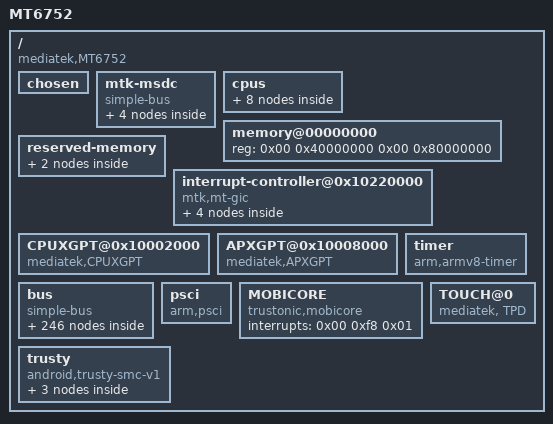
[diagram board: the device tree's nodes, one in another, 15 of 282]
/dts-v1/;

/ {
	model = "MT6752";
	compatible = "mediatek,MT6752";
	interrupt-parent = <0x01>;
	#address-cells = <0x02>;
	#size-cells = <0x02>;

	chosen {
		bootargs = "console=tty0 root=/dev/ram initrd=0x44000000,0x200000 loglevel=8";
	};

	mtk-msdc {
		compatible = "simple-bus";
		#address-cells = <0x01>;
		#size-cells = <0x01>;
		ranges = <0x00 0x00 0x00 0xffffffff>;

		MSDC0@0x11230000 {
			compatible = "mediatek,MSDC0";
			reg = <0x11230000 0x10000 0x10001e84 0x02>;
			interrupts = <0x00 0x4f 0x08>;
		};

		MSDC1@0x11240000 {
			compatible = "mediatek,MSDC1";
			reg = <0x11240000 0x10000 0x10001e84 0x02>;
			interrupts = <0x00 0x50 0x08>;
		};

		MSDC2@0x11250000 {
			compatible = "mediatek,MSDC2";
			reg = <0x11250000 0x10000 0x10001e84 0x02>;
			interrupts = <0x00 0x51 0x08>;
		};

		MSDC3@0x11260000 {
			compatible = "mediatek,MSDC3";
			reg = <0x11260000 0x10000 0x10001e84 0x02>;
			interrupts = <0x00 0x52 0x08>;
		};
	};

	cpus {
		#address-cells = <0x01>;
		#size-cells = <0x00>;

		cpu@0 {
			device_type = "cpu";
			compatible = "arm,cortex-a53";
			reg = <0x00>;
			enable-method = "mt-boot";
			cpu-release-addr = <0x00 0x40000200>;
			clock-frequency = <0x77359400>;
			linux,phandle = <0x02>;
			phandle = <0x02>;
		};

		cpu@1 {
			device_type = "cpu";
			compatible = "arm,cortex-a53";
			reg = <0x01>;
			enable-method = "mt-boot";
			cpu-release-addr = <0x00 0x40000200>;
			clock-frequency = <0x77359400>;
			linux,phandle = <0x03>;
			phandle = <0x03>;
		};

		cpu@2 {
			device_type = "cpu";
			compatible = "arm,cortex-a53";
			reg = <0x02>;
			enable-method = "mt-boot";
			cpu-release-addr = <0x00 0x40000200>;
			clock-frequency = <0x77359400>;
			linux,phandle = <0x04>;
			phandle = <0x04>;
		};

		cpu@3 {
			device_type = "cpu";
			compatible = "arm,cortex-a53";
			reg = <0x03>;
			enable-method = "mt-boot";
			cpu-release-addr = <0x00 0x40000200>;
			clock-frequency = <0x77359400>;
			linux,phandle = <0x05>;
			phandle = <0x05>;
		};

		cpu@4 {
			device_type = "cpu";
			compatible = "arm,cortex-a53";
			reg = <0x100>;
			enable-method = "mt-boot";
			cpu-release-addr = <0x00 0x40000200>;
			clock-frequency = <0x77359400>;
		};

		cpu@5 {
			device_type = "cpu";
			compatible = "arm,cortex-a53";
			reg = <0x101>;
			enable-method = "mt-boot";
			cpu-release-addr = <0x00 0x40000200>;
			clock-frequency = <0x77359400>;
		};

		cpu@6 {
			device_type = "cpu";
			compatible = "arm,cortex-a53";
			reg = <0x102>;
			enable-method = "mt-boot";
			cpu-release-addr = <0x00 0x40000200>;
			clock-frequency = <0x77359400>;
		};

		cpu@7 {
			device_type = "cpu";
			compatible = "arm,cortex-a53";
			reg = <0x103>;
			enable-method = "mt-boot";
			cpu-release-addr = <0x00 0x40000200>;
			clock-frequency = <0x77359400>;
		};
	};

	memory@00000000 {
		device_type = "memory";
		reg = <0x00 0x40000000 0x00 0x80000000>;
	};

	reserved-memory {
		#address-cells = <0x02>;
		#size-cells = <0x02>;
		ranges;

		reserve-memory-ccci_md1 {
			compatible = "reserve-memory-ccci_md1";
			no-map;
			size = <0x00 0x5200000>;
			alignment = <0x00 0x2000000>;
			alloc-ranges = <0x00 0x40000000 0x00 0xc0000000>;
		};

		consys-reserve-memory {
			compatible = "consys-reserve-memory";
			no-map;
			size = <0x00 0x200000>;
			alignment = <0x00 0x200000>;
		};
	};

	interrupt-controller@0x10220000 {
		compatible = "mtk,mt-gic";
		#interrupt-cells = <0x03>;
		#address-cells = <0x00>;
		interrupt-controller;
		reg = <0x00 0x10221000 0x00 0x1000 0x00 0x10222000 0x00 0x1000 0x00 0x10200620 0x00 0x1000>;
		interrupts = <0x01 0x09 0xf04>;
		linux,phandle = <0x01>;
		phandle = <0x01>;

		gic-cpuif@0 {
			compatible = "arm,gic-cpuif";
			cpuif-id = <0x00>;
			cpu = <0x02>;
		};

		gic-cpuif@1 {
			compatible = "arm,gic-cpuif";
			cpuif-id = <0x01>;
			cpu = <0x03>;
		};

		gic-cpuif@2 {
			compatible = "arm,gic-cpuif";
			cpuif-id = <0x02>;
			cpu = <0x04>;
		};

		gic-cpuif@3 {
			compatible = "arm,gic-cpuif";
			cpuif-id = <0x03>;
			cpu = <0x05>;
		};
	};

	CPUXGPT@0x10002000 {
		compatible = "mediatek,CPUXGPT";
		reg = <0x00 0x10200000 0x00 0x1000>;
		interrupts = <0x00 0x40 0x04 0x00 0x41 0x04 0x00 0x42 0x04 0x00 0x43 0x04 0x00 0x44 0x04 0x00 0x45 0x04 0x00 0x46 0x04 0x00 0x47 0x04>;
	};

	APXGPT@0x10008000 {
		compatible = "mediatek,APXGPT";
		reg = <0x00 0x10008000 0x00 0x1000>;
		interrupts = <0x00 0x98 0x08>;
		clock-frequency = <0xc65d40>;
	};

	timer {
		compatible = "arm,armv8-timer";
		interrupts = <0x01 0x0d 0x08 0x01 0x0e 0x08 0x01 0x0b 0x08 0x01 0x0a 0x08>;
		clock-frequency = <0xc65d40>;
	};

	bus {
		compatible = "simple-bus";
		#address-cells = <0x01>;
		#size-cells = <0x01>;
		ranges = <0x00 0x00 0x00 0xffffffff>;

		TOPCKGEN@0x10000000 {
			compatible = "mediatek,TOPCKGEN";
			reg = <0x10000000 0x1000>;
		};

		INFRACFG_AO@0x10001000 {
			compatible = "mediatek,INFRACFG_AO";
			reg = <0x10001000 0x1000>;
		};

		usb2jtag@10001000 {
			compatible = "mediatek,usb2jtag_v1";
			reg = <0x10001000 0x1000 0x11210000 0x1000>;
		};

		IOCFG_L@0x10002000 {
			compatible = "mediatek,IOCFG_L";
			reg = <0x10002000 0x400>;
		};

		IOCFG_B@0x10002400 {
			compatible = "mediatek,IOCFG_B";
			reg = <0x10002400 0x400>;
		};

		IOCFG_R@0x10002800 {
			compatible = "mediatek,IOCFG_R";
			reg = <0x10002800 0x400>;
		};

		IOCFG_T@0x10002C00 {
			compatible = "mediatek,IOCFG_T";
			reg = <0x10002c00 0x400>;
		};

		PERICFG@0x10003000 {
			compatible = "mediatek,PERICFG";
			reg = <0x10003000 0x1000>;
		};

		DRAMC0@0x10004000 {
			compatible = "mediatek,DRAMC0";
			reg = <0x10004000 0x1000>;
		};

		GPIO@0x10005000 {
			compatible = "mediatek,GPIO";
			reg = <0x10005000 0x1000>;
		};

		SLEEP@0x10006000 {
			compatible = "mediatek,SLEEP";
			reg = <0x10006000 0x1000>;
			interrupts = <0x00 0xa3 0x08 0x00 0xa4 0x08 0x00 0xa5 0x08 0x00 0xa6 0x08 0x00 0xa7 0x08 0x00 0xa8 0x08 0x00 0xa9 0x08 0x00 0xaa 0x08>;
		};

		TOPRGU@0x10007000 {
			compatible = "mediatek,TOPRGU";
			reg = <0x10007000 0x1000>;
			interrupts = <0x00 0x80 0x02>;
		};

		RSVD@0x10009000 {
			compatible = "mediatek,RSVD";
			reg = <0x10009000 0x1000>;
		};

		hacc@0x1000A000 {
			compatible = "mediatek,hacc";
			reg = <0x1000a000 0x1000>;
			interrupts = <0x00 0xac 0x08>;
		};

		eintc: EINTC@0x1000B000 {
			compatible = "mtk,mt-eic";
			reg = <0x1000b000 0x1000>;
			interrupts = <0x00 0x99 0x04>;
			#interrupt-cells = <0x02>;
			interrupt-controller;
			max_eint_num = <0x40>;
			mapping_table_entry = <0x40>;
			mapping_table = <0x18 0x18 0x19 0x19 0x1f 0x1a 0x20 0x1b 0x21 0x1c 0x22 0x1d 0x23 0x00 0x24 0x01 0x25 0x02 0x3a 0x1e 0x3b 0x1f 0x3c 0x20 0x3d 0x21 0x3e 0x22 0x3f 0x3f 0x44 0x23 0x45 0x24 0x46 0x25 0x47 0x26 0x48 0x27 0x49 0x28 0x61 0x29 0x72 0x03 0x73 0x04 0x74 0x05 0x75 0x06 0x76 0x07 0x77 0x08 0x78 0x32 0x79 0x36 0x7a 0x2a 0x7b 0x2b 0x7c 0x2c 0x7d 0x2d 0x7e 0x2e 0x7f 0x2f 0x80 0x30 0x81 0x31 0x82 0x0b 0x83 0x0c 0x84 0x0d 0x85 0x0e 0x86 0x09 0x87 0x33 0x88 0x0f 0x89 0x34 0x8a 0x35 0x8b 0x0a 0x8c 0x10 0x8d 0x11 0x8e 0x12 0x8f 0x13 0x90 0x14 0x91 0x15 0x92 0x16 0x93 0x17 0x94 0x37 0x95 0x38 0x96 0x39 0x97 0x3a 0x98 0x3b 0x99 0x3c 0x9a 0x3d 0x9b 0x3e>;
			linux,phandle = <0x06>;
			phandle = <0x06>;

			CHR_STAT@0 {
				compatible = "mediatek, CHR_STAT-eint";
				interrupt-parent = <0x06>;
				interrupts = <0x23 0x08>;
				debounce = <0x23 0x00>;
			};

			GSE_1@2 {
				compatible = "mediatek, GSE_1-eint";
				interrupt-parent = <0x06>;
				interrupts = <0x25 0x04>;
				debounce = <0x25 0x00>;
			};

			MSE@9 {
				compatible = "mediatek, MSE-eint";
				interrupt-parent = <0x06>;
				interrupts = <0x86 0x08>;
				debounce = <0x86 0x00>;
			};

			TOUCH_PANEL@10 {
				compatible = "mediatek, TOUCH_PANEL-eint";
				interrupt-parent = <0x06>;
				interrupts = <0x8b 0x01>;
				debounce = <0x8b 0x00>;
			};

			ALS@11 {
				compatible = "mediatek, ALS-eint";
				interrupt-parent = <0x06>;
				interrupts = <0x82 0x08>;
				debounce = <0x82 0x00>;
			};

			IRQ_NFC@13 {
				compatible = "mediatek, IRQ_NFC-eint";
				interrupt-parent = <0x06>;
				interrupts = <0x84 0x04>;
				debounce = <0x84 0x00>;
			};

			EXT_BUCK_OC@14 {
				compatible = "mediatek, EXT_BUCK_OC-eint";
				interrupt-parent = <0x06>;
				interrupts = <0x85 0x04>;
				debounce = <0x85 0x00>;
			};

			GYRO@17 {
				compatible = "mediatek, GYRO-eint";
				interrupt-parent = <0x06>;
				interrupts = <0x8d 0x04>;
				debounce = <0x8d 0x00>;
			};

			EINT_HDMI_HPD@21 {
				compatible = "mediatek, EINT_HDMI_HPD-eint";
				interrupt-parent = <0x06>;
				interrupts = <0x91 0x08>;
				debounce = <0x91 0x00>;
			};

			MSDC1_INS@22 {
				compatible = "mediatek, MSDC1_INS-eint";
				interrupt-parent = <0x06>;
				interrupts = <0x92 0x04>;
				debounce = <0x92 0x3e8>;
			};

			KPD_SLIDE@23 {
				compatible = "mediatek, KPD_SLIDE-eint";
				interrupt-parent = <0x06>;
				interrupts = <0x93 0x08>;
				debounce = <0x93 0x7d00>;
			};

			ACCDET@40 {
				compatible = "mediatek, ACCDET-eint";
				interrupt-parent = <0x06>;
				interrupts = <0x49 0x08>;
				debounce = <0x49 0x3e80>;
			};
		};

		EMIMPU@0x10203000 {
			compatible = "mediatek,EMIMPU";
			reg = <0x10203000 0x1000>;
			interrupts = <0x00 0x85 0x08>;
		};

		APMIXED@0x1000C000 {
			compatible = "mediatek,APMIXED";
			reg = <0x1000c000 0x1000>;
			interrupts = <0x00 0x88 0x01>;
		};

		FHCTL@0x1000CF00 {
			compatible = "mediatek,FHCTL";
			reg = <0x1000cf00 0x100>;
		};

		PWRAP@0x1000D000 {
			compatible = "mediatek,PWRAP";
			reg = <0x1000d000 0x1000>;
			interrupts = <0x00 0xa1 0x04>;
		};

		DEVAPC_AO@0x1000E000 {
			compatible = "mediatek,DEVAPC_AO";
			reg = <0x1000e000 0x1000>;
		};

		DDRPHY@0x1000F000 {
			compatible = "mediatek,DDRPHY";
			reg = <0x1000f000 0x1000>;
		};

		KP@0x10010000 {
			compatible = "mediatek,KP";
			reg = <0x10010000 0x1000>;
			interrupts = <0x00 0xa2 0x02>;
		};

		TOPMISC@0x10011000 {
			compatible = "mediatek,TOPMISC";
			reg = <0x10011000 0x1000>;
		};

		SCP_SRAM@0x10020000 {
			compatible = "mediatek,SCP_SRAM";
			reg = <0x10020000 0x38000>;
		};

		SCP_CFGREG@0x10058000 {
			compatible = "mediatek,SCP_CFGREG";
			reg = <0x10058000 0x400>;
			interrupts = <0x00 0xae 0x04>;
		};

		SCP_MAD@0x10058400 {
			compatible = "mediatek,SCP_MAD";
			reg = <0x10058400 0x400>;
		};

		SCP_INTC@0x10058800 {
			compatible = "mediatek,SCP_INTC";
			reg = <0x10058800 0x400>;
		};

		SCP_TIMER@0x10058C00 {
			compatible = "mediatek,SCP_TIMER";
			reg = <0x10058c00 0x400>;
		};

		SCP_CLK_CTRL@0x10059000 {
			compatible = "mediatek,SCP_CLK_CTRL";
			reg = <0x10059000 0x400>;
		};

		SCP_I2C0@0x10059400 {
			compatible = "mediatek,SCP_I2C0";
			reg = <0x10059400 0x400>;
		};

		SCP_I2C1@0x10059800 {
			compatible = "mediatek,SCP_I2C1";
			reg = <0x10059800 0x400>;
		};

		SCP_I2C2@0x10059C00 {
			compatible = "mediatek,SCP_I2C2";
			cell-index = <0x02>;
			reg = <0x10059c00 0x400>;
		};

		SCP_GPIO@0x1005A000 {
			compatible = "mediatek,SCP_GPIO";
			reg = <0x1005a000 0x400>;
		};

		SCP_UART@0x1005A400 {
			compatible = "mediatek,SCP_UART";
			reg = <0x1005a400 0x400>;
		};

		SCP_CIRQ_EINT@0x1005A800 {
			compatible = "mediatek,SCP_CIRQ_EINT";
			reg = <0x1005a800 0x400>;
		};

		SCP_PMICWP2P@0x1005E000 {
			compatible = "mediatek,SCP_PMICWP2P";
			reg = <0x1005e000 0x1000>;
		};

		SCP_PMICWP2P@0x1005F000 {
			compatible = "mediatek,SCP_PMICWP2P";
			reg = <0x1005f000 0x1000>;
		};

		DBGAPB_BASE@0x1011A000 {
			compatible = "mediatek,DBGAPB_BASE";
			reg = <0x1011a000 0x100>;
		};

		DBG_ETB@0x10100000 {
			compatible = "mediatek,DBG_ETB";
			reg = <0x10410000 0x10000 0x10430000 0x10000 0x10440000 0x10000 0x104a0000 0x10000>;
		};

		DBG_DEBUG {
			compatible = "mediatek,DBG_DEBUG";
			num = <0x08>;
			reg = <0x10810000 0x1000 0x10910000 0x1000 0x10a10000 0x1000 0x10b10000 0x1000 0x10c10000 0x1000 0x10d10000 0x1000 0x10e10000 0x1000 0x10f10000 0x1000>;
		};

		DBG_ETM {
			compatible = "mediatek,DBG_ETM";
			num = <0x08>;
			reg = <0x10840000 0x1000 0x10940000 0x1000 0x10a40000 0x1000 0x10b40000 0x1000 0x10c40000 0x1000 0x10d40000 0x1000 0x10e40000 0x1000 0x10f40000 0x1000>;
		};

		BAT_METTER {
			compatible = "mediatek,bat_meter";
		};

		BAT_NOTIFY {
			compatible = "mediatek,bat_notify";
		};

		MCUCFG@0x10200000 {
			compatible = "mediatek,MCUCFG";
			reg = <0x10200000 0x1000>;
		};

		INFRACFG@0x10201000 {
			compatible = "mediatek,INFRACFG";
			reg = <0x10201000 0x1000>;
		};

		SRAMROM@0x10202000 {
			compatible = "mediatek,SRAMROM";
			reg = <0x10202000 0x1000>;
		};

		EMI@0x10203000 {
			compatible = "mediatek,EMI";
			reg = <0x10203000 0x1000>;
			interrupts = <0x00 0x87 0x08>;
		};

		sys_cirq@10204000 {
			compatible = "mediatek,SYS_CIRQ";
			reg = <0x10204000 0x1000>;
			interrupts = <0x00 0xf0 0x08>;
			cirq_num = <0xa8>;
			spi_start_offset = <0x48>;
		};

		M4U@0x10205000 {
			cell-index = <0x00>;
			compatible = "mediatek,M4U";
			reg = <0x10205000 0x1000>;
			interrupts = <0x00 0x93 0x08>;
		};

		EFUSEC@0x10206000 {
			compatible = "mediatek,EFUSEC";
			reg = <0x10206000 0x1000>;
			interrupts = <0x00 0x89 0x01>;
		};

		DEVAPC@0x10207000 {
			compatible = "mediatek,DEVAPC";
			reg = <0x10207000 0x1000>;
			interrupts = <0x00 0x86 0x08>;
		};

		BUS_DBG@0x10208000 {
			compatible = "mediatek,BUS_DBG";
			reg = <0x10208000 0x1000>;
			interrupts = <0x00 0x84 0x08>;
		};

		AP_CCIF0@0x10209000 {
			compatible = "mediatek,AP_CCIF0";
			reg = <0x10209000 0x1000>;
		};

		MD_CCIF0@0x1020A000 {
			compatible = "mediatek,MD_CCIF0";
			reg = <0x1020a000 0x1000>;
		};

		AP_CCIF1@0x1020B000 {
			compatible = "mediatek,AP_CCIF1";
			reg = <0x1020b000 0x1000>;
			interrupts = <0x00 0x8d 0x08 0x00 0xaf 0x02>;
			cell-index = <0x01>;
			ccif,major = <0xa9>;
			ccif,minor_base = <0x00>;
			ccif,capability = <0x00>;
			md_smem_size = <0x400000>;
		};

		MD_CCIF1@0x1020C000 {
			compatible = "mediatek,MD_CCIF1";
			reg = <0x1020c000 0x1000>;
		};

		INFRA_MBIST@0x1020D000 {
			compatible = "mediatek,INFRA_MBIST";
			reg = <0x1020d000 0x1000>;
		};

		DRAMC_NAO@0x1020E000 {
			compatible = "mediatek,DRAMC_NAO";
			reg = <0x1020e000 0x1000>;
		};

		TRNG@0x1020F000 {
			compatible = "mediatek,TRNG";
			reg = <0x1020f000 0x1000>;
			interrupts = <0x00 0x8c 0x08>;
		};

		GCPU@0x10210000 {
			compatible = "mediatek,gcpu";
			reg = <0x10210000 0x1000>;
			interrupts = <0x00 0x96 0x08>;
		};

		MD2MD_MD1_CCIF0@0x10211000 {
			compatible = "mediatek,MD2MD_MD1_CCIF0";
			reg = <0x10211000 0x1000>;
		};

		gce@10212000 {
			compatible = "mediatek,gce";
			reg = <0x10212000 0x1000>;
			interrupts = <0x00 0x8f 0x08 0x00 0x90 0x08>;
			disp_mutex_reg = <0x14015000 0x1000>;
			g3d_config_base = <0x13000000 0x00 0xffff0000>;
			mmsys_config_base = <0x14000000 0x01 0xffff0000>;
			disp_dither_base = <0x14010000 0x02 0xffff0000>;
			mm_na_base = <0x14020000 0x03 0xffff0000>;
			imgsys_base = <0x15000000 0x04 0xffff0000>;
			vdec_gcon_base = <0x16000000 0x05 0xffff0000>;
			venc_gcon_base = <0x17000000 0x06 0xffff0000>;
			conn_peri_base = <0x18000000 0x07 0xffff0000>;
			topckgen_base = <0x10000000 0x08 0xffff0000>;
			kp_base = <0x10010000 0x09 0xffff0000>;
			scp_sram_base = <0x10020000 0x0a 0xffff0000>;
			infra_na3_base = <0x10030000 0x0b 0xffff0000>;
			infra_na4_base = <0x10040000 0x0c 0xffff0000>;
			scp_base = <0x10050000 0x0d 0xffff0000>;
			mcucfg_base = <0x10200000 0x0e 0xffff0000>;
			gcpu_base = <0x10210000 0x0f 0xffff0000>;
			usb0_base = <0x11200000 0x10 0xffff0000>;
			usb_sif_base = <0x11210000 0x11 0xffff0000>;
			audio_base = <0x11220000 0x12 0xffff0000>;
			msdc0_base = <0x11230000 0x13 0xffff0000>;
			msdc1_base = <0x11240000 0x14 0xffff0000>;
			msdc2_base = <0x11250000 0x15 0xffff0000>;
			msdc3_base = <0x11260000 0x16 0xffff0000>;
			mdp_rdma0_sof = <0x00>;
			mdp_rsz0_sof = <0x01>;
			mdp_rsz1_sof = <0x02>;
			mdp_tdshp_sof = <0x03>;
			mdp_wdma_sof = <0x04>;
			mdp_wrot_sof = <0x05>;
			disp_ovl0_sof = <0x06>;
			disp_ovl1_sof = <0x07>;
			disp_rdma0_sof = <0x08>;
			disp_rdma1_sof = <0x09>;
			disp_wdma0_sof = <0x0a>;
			disp_color_sof = <0x0b>;
			disp_ccorr_sof = <0x0c>;
			disp_aal_sof = <0x0d>;
			disp_gamma_sof = <0x0e>;
			disp_dither_sof = <0x0f>;
			disp_ufoe_sof = <0x10>;
			disp_pwm0_sof = <0x11>;
			disp_wdma1_sof = <0x12>;
			ufod_rdma0_l0_sof = <0x13>;
			ufod_rdma0_l1_sof = <0x14>;
			ufod_rdma0_l2_sof = <0x15>;
			ufod_rdma0_l3_sof = <0x16>;
			ufod_rdma1_l0_sof = <0x17>;
			ufod_rdma1_l1_sof = <0x18>;
			ufod_rdma1_l2_sof = <0x19>;
			ufod_rdma1_l3_sof = <0x1a>;
			mdp_rdma0_frame_done = <0x1b>;
			mdp_rsz0_frame_done = <0x1c>;
			mdp_rsz1_frame_done = <0x1d>;
			mdp_tdshp_frame_done = <0x1e>;
			mdp_wdma_frame_done = <0x1f>;
			mdp_wrot_write_frame_done = <0x20>;
			mdp_wrot_read_frame_done = <0x21>;
			disp_ovl0_frame_done = <0x22>;
			disp_ovl1_frame_done = <0x23>;
			disp_rdma0_frame_done = <0x24>;
			disp_rdma1_frame_done = <0x25>;
			disp_wdma0_frame_done = <0x26>;
			disp_color_frame_done = <0x27>;
			disp_ccorr_frame_done = <0x28>;
			disp_aal_frame_done = <0x29>;
			disp_gamma_frame_done = <0x2a>;
			disp_dither_frame_done = <0x2b>;
			disp_ufoe_frame_done = <0x2c>;
			disp_dpi0_frame_done = <0x2d>;
			disp_wdma1_frame_done = <0x2e>;
			ufod_rdma0_l0_frame_done = <0x2f>;
			ufod_rdma0_l1_frame_done = <0x30>;
			ufod_rdma0_l2_frame_done = <0x31>;
			ufod_rdma0_l3_frame_done = <0x32>;
			ufod_rdma1_l0_frame_done = <0x33>;
			ufod_rdma1_l1_frame_done = <0x34>;
			ufod_rdma1_l2_frame_done = <0x35>;
			ufod_rdma1_l3_frame_done = <0x36>;
			stream_done_0 = <0x37>;
			stream_done_1 = <0x38>;
			stream_done_2 = <0x39>;
			stream_done_3 = <0x3a>;
			stream_done_4 = <0x3b>;
			stream_done_5 = <0x3c>;
			stream_done_6 = <0x3d>;
			stream_done_7 = <0x3e>;
			stream_done_8 = <0x3f>;
			stream_done_9 = <0x40>;
			buf_underrun_event_0 = <0x41>;
			buf_underrun_event_1 = <0x42>;
			dsi0_te_event = <0x43>;
			isp_frame_done_p2_2 = <0x81>;
			isp_frame_done_p2_1 = <0x82>;
			isp_frame_done_p2_0 = <0x83>;
			isp_frame_done_p1_1 = <0x84>;
			isp_frame_done_p1_0 = <0x85>;
			camsv_2_pass1_done = <0x86>;
			camsv_1_pass1_done = <0x87>;
			seninf_cam1_2_3_fifo_full = <0x88>;
			seninf_cam0_fifo_full = <0x89>;
			venc_done = <0x101>;
			jpgenc_done = <0x102>;
			jpgdec_done = <0x103>;
			venc_mb_done = <0x104>;
			venc_128byte_cnt_done = <0x105>;
			apxgpt2_count = <0x10008028>;
		};

		MD2MD_MD2_CCIF0@0x10213000 {
			compatible = "mediatek,MD2MD_MD2_CCIF0";
			reg = <0x10213000 0x1000>;
		};

		PERISYS_IOMMU@0x10214000 {
			cell-index = <0x01>;
			compatible = "mediatek,PERISYS_IOMMU";
			reg = <0x10214000 0x1000>;
			interrupts = <0x00 0x91 0x08>;
		};

		MIPI_TX0@0x10215000 {
			compatible = "mediatek,MIPI_TX0";
			reg = <0x10215000 0x1000>;
		};

		MIPI_RX_ANA_CSI0@0x10217000 {
			compatible = "mediatek,MIPI_RX_ANA_CSI0";
			reg = <0x10217000 0x1000>;
			interrupts = <0x00 0x8a 0x01>;
		};

		MIPI_RX_ANA_CSI1@0x10218000 {
			compatible = "mediatek,MIPI_RX_ANA_CSI1";
			reg = <0x10218000 0x1000>;
		};

		GIC@0x10220000 {
			compatible = "mediatek,GIC";
			reg = <0x10220000 0x8000>;
		};

		CCI400@0x10390000 {
			compatible = "mediatek,CCI400";
			reg = <0x10390000 0x10000>;
		};

		DBGAPB@0x10400000 {
			compatible = "mediatek,DBGAPB";
			reg = <0x10400000 0xc00000>;
			interrupts = <0x00 0x83 0x08>;
		};

		AP_DMA@0x11000000 {
			compatible = "mediatek,AP_DMA";
			reg = <0x11000000 0x1000>;
			interrupts = <0x00 0x6f 0x08>;
		};

		AUXADC@0x11001000 {
			compatible = "mediatek,AUXADC";
			reg = <0x11001000 0x1000>;
			interrupts = <0x00 0x4c 0x02>;
		};

		AP_DMA_UART0_TX@0x11000300 {
			compatible = "mediatek,AP_DMA_UART0_TX";
			reg = <0x11000300 0x80>;
			interrupts = <0x00 0x66 0x08>;
		};

		AP_DMA_UART0_RX@0x11000380 {
			compatible = "mediatek,AP_DMA_UART0_RX";
			reg = <0x11000380 0x80>;
			interrupts = <0x00 0x67 0x08>;
		};

		AP_DMA_UART1_TX@0x11000400 {
			compatible = "mediatek,AP_DMA_UART1_TX";
			reg = <0x11000400 0x80>;
			interrupts = <0x00 0x68 0x08>;
		};

		AP_DMA_UART1_RX@0x11000480 {
			compatible = "mediatek,AP_DMA_UART1_RX";
			reg = <0x11000480 0x80>;
			interrupts = <0x00 0x69 0x08>;
		};

		AP_DMA_UART2_TX@0x11000500 {
			compatible = "mediatek,AP_DMA_UART2_TX";
			reg = <0x11000500 0x80>;
			interrupts = <0x00 0x6a 0x08>;
		};

		AP_DMA_UART2_RX@0x11000580 {
			compatible = "mediatek,AP_DMA_UART2_RX";
			reg = <0x11000580 0x80>;
			interrupts = <0x00 0x6b 0x08>;
		};

		AP_DMA_UART3_TX@0x11000600 {
			compatible = "mediatek,AP_DMA_UART3_TX";
			reg = <0x11000600 0x80>;
			interrupts = <0x00 0x6c 0x08>;
		};

		AP_DMA_UART3_RX@0x11000680 {
			compatible = "mediatek,AP_DMA_UART3_RX";
			reg = <0x11000680 0x80>;
			interrupts = <0x00 0x6d 0x08>;
		};

		AP_UART0@0x11002000 {
			cell-index = <0x00>;
			compatible = "mediatek,AP_UART0";
			reg = <0x11002000 0x1000>;
			interrupts = <0x00 0x5b 0x08>;
		};

		AP_UART1@0x11003000 {
			cell-index = <0x01>;
			compatible = "mediatek,AP_UART1";
			reg = <0x11003000 0x1000>;
			interrupts = <0x00 0x5c 0x08>;
		};

		AP_UART2@0x11004000 {
			cell-index = <0x02>;
			compatible = "mediatek,AP_UART2";
			reg = <0x11004000 0x1000>;
			interrupts = <0x00 0x5d 0x08>;
		};

		AP_UART3@0x11005000 {
			cell-index = <0x03>;
			compatible = "mediatek,AP_UART3";
			reg = <0x11005000 0x1000>;
			interrupts = <0x00 0x5e 0x08>;
		};

		PWM@0x11006000 {
			compatible = "mediatek,PWM";
			reg = <0x11006000 0x1000>;
			interrupts = <0x00 0x4d 0x08>;
		};

		I2C0@0x11007000 {
			compatible = "mediatek,I2C0";
			cell-index = <0x00>;
			reg = <0x11007000 0x1000>;
			#address-cells = <0x01>;
			#size-cells = <0x00>;
			interrupts = <0x00 0x54 0x08>;

			// gt9xx@5d {
			//	compatible = "gt9xx";
			//	reg = <0x5d>;
			//};

			//bq24296@6b {
			//	compatible = "bq24296";
			//	reg = <0x6b>;
			//};

			//mt6306@64 {
			//	compatible = "mediatek,mt6306";
			//	reg = <0x64>;
			//};
		};

		I2C1@0x11008000 {
			compatible = "mediatek,I2C1";
			cell-index = <0x01>;
			reg = <0x11008000 0x1000>;
			#address-cells = <0x01>;
			#size-cells = <0x00>;
			interrupts = <0x00 0x55 0x08>;

			//yas530@2e {
			//	compatible = "yamaha530";
			//	reg = <0x2e>;
			//};

			/* mpu-6515@68 {
				compatible = "mpu-6515";
				reg = <0x68>;
			};

			bmp180@77 {
				compatible = "bmp180";
				reg = <0x77>;
			};

			cm36652@60 {
				compatble = "cm36652";
				reg = <0x60>;
			};

			mt6605@28 {
				compatible = "mediatek,mt6605";
				reg = <0x28>;
			}; */
		};

		I2C2@0x11009000 {
			compatible = "mediatek,I2C2";
			cell-index = <0x03>;
			reg = <0x11009000 0x1000>;
			#address-cells = <0x01>;
			#size-cells = <0x00>;
			interrupts = <0x00 0x56 0x08>;
		};

		SPI1@0x1100A000 {
			compatible = "mediatek,SPI1";
			cell-index = <0x00>;
			spi-padmacro = <0x00>;
			reg = <0x1100a000 0x1000>;
			interrupts = <0x00 0x76 0x08>;
		};

		THERM_CTRL@0x1100B000 {
			compatible = "mediatek,THERM_CTRL";
			reg = <0x1100b000 0x1000>;
			interrupts = <0x00 0x4e 0x08>;
		};

		PTP_FSM@0x1100B000 {
			compatible = "mediatek,PTP_FSM";
			reg = <0x1100b000 0x1000>;
			interrupts = <0x00 0x7d 0x08>;
		};

		AP_DMA_BTIF_TX@0x11000700 {
			compatible = "mediatek,AP_DMA_BTIF_TX";
			reg = <0x11000700 0x80>;
			interrupts = <0x00 0x6e 0x08>;
		};

		AP_DMA_BTIF_RX@0x11000780 {
			compatible = "mediatek,AP_DMA_BTIF_RX";
			reg = <0x11000780 0x80>;
			interrupts = <0x00 0x6f 0x08>;
		};

		BTIF@0x1100C000 {
			compatible = "mediatek,BTIF";
			reg = <0x1100c000 0x1000>;
			interrupts = <0x00 0x70 0x08>;
		};

		mt3326-gps@0xffffffff {
			compatible = "mediatek,mt3326-gps";
		};

		BTCVSD@0x18000000 {
			compatible = "mediatek,audio_bt_cvsd";
			offset = <0xf00 0x800 0xfd0 0xfd4 0xfd8>;
			reg = <0x10001000 0x1000 0x18000000 0x10000 0x18080000 0x8000>;
			interrupts = <0x00 0xec 0x08>;
		};

		CONSYS@0x18070000 {
			compatible = "mediatek,CONSYS";
			reg = <0x18070000 0x200 0x10007000 0x100 0x10000000 0x2000 0x10006000 0x1000>;
			interrupts = <0x00 0xed 0x08 0x00 0xeb 0x08>;
		};

		WIFI@0x180F0000 {
			compatible = "mediatek,WIFI";
			reg = <0x180f0000 0x5c>;
			interrupts = <0x00 0xee 0x08>;
		};

		NFI@0x1100D000 {
			compatible = "mediatek,NFI";
			reg = <0x1100d000 0x1000>;
			interrupts = <0x00 0x60 0x08>;
		};

		NFIECC@0x1100E000 {
			compatible = "mediatek,NFIECC";
			reg = <0x1100e000 0x1000>;
			interrupts = <0x00 0x5f 0x08>;
		};

		USB0@0x11200000 {
			compatible = "mediatek,USB0";
			cell-index = <0x00>;
			reg = <0x11200000 0x10000 0x11210000 0x10000>;
			interrupts = <0x00 0x48 0x08>;
			mode = <0x02>;
			multipoint = <0x01>;
			dyn_fifo = <0x01>;
			soft_con = <0x01>;
			dma = <0x01>;
			num_eps = <0x10>;
			dma_channels = <0x08>;
			iddig_gpio = <0x8e 0x01>;
			drvvbus_gpio = <0x8f 0x00>;
		};

		BATTERY {
			compatible = "mediatek,battery";
		};

		AUDIO@0x11220000 {
			compatible = "mediatek,AUDIO";
			reg = <0x11220000 0x10000>;
			interrupts = <0x00 0x8e 0x08>;
		};

		MT_SOC_DL1_PCM@0x11220000 {
			compatible = "mediatek,mt_soc_pcm_dl1";
			reg = <0x11220000 0x1000>;
			interrupts = <0x00 0x8e 0x08>;
			audclk-gpio = <0x18 0x00>;
			audmiso-gpio = <0x19 0x00>;
			audmosi-gpio = <0x1a 0x00>;
			vowclk-gpio = <0x94 0x00>;
			extspkamp-gpio = <0x4e 0x00>;
			i2s1clk-gpio = <0x87 0x00>;
			i2s1dat-gpio = <0x89 0x00>;
			i2s1mclk-gpio = <0x86 0x00>;
			i2s1ws-gpio = <0x88 0x00>;
		};

		MT_SOC_UL1_PCM@0x11220000 {
			compatible = "mediatek,mt_soc_pcm_capture";
		};

		MT_SOC_VOICE_MD1@0x11220000 {
			compatible = "mediatek,mt_soc_pcm_voice_md1";
		};

		MT_SOC_HDMI_PCM@0x11220000 {
			compatible = "mediatek,mt_soc_pcm_hdmi";
		};

		MT_SOC_ULDLLOOPBACK_PCM@0x11220000 {
			compatible = "mediatek,mt_soc_pcm_uldlloopback";
		};

		MT_SOC_I2S0_PCM@0x11220000 {
			compatible = "mediatek,mt_soc_pcm_dl1_i2s0";
		};

		MT_SOC_MRGRX_PCM@0x11220000 {
			compatible = "mediatek,mt_soc_pcm_mrgrx";
		};

		MT_SOC_MRGRX_AWB_PCM@0x11220000 {
			compatible = "mediatek,mt_soc_pcm_mrgrx_awb";
		};

		MT_SOC_FM_I2S_PCM@0x11220000 {
			compatible = "mediatek,mt_soc_pcm_fm_i2s";
		};

		MT_SOC_FM_I2S_AWB_PCM@0x11220000 {
			compatible = "mediatek,mt_soc_pcm_fm_i2s_awb";
		};

		MT_SOC_I2S0DL1_PCM@0x11220000 {
			compatible = "mediatek,mt_soc_pcm_dl1_i2s0Dl1";
		};

		MT_SOC_DL1_AWB_PCM@0x11220000 {
			compatible = "mediatek,mt_soc_pcm_dl1_awb";
		};

		MT_SOC_VOICE_MD1_BT@0x11220000 {
			compatible = "mediatek,mt_soc_pcm_voice_md1_bt";
		};

		MT_SOC_VOIP_BT_OUT@0x11220000 {
			compatible = "mediatek,mt_soc_pcm_dl1_bt";
		};

		MT_SOC_VOIP_BT_IN@0x11220000 {
			compatible = "mediatek,mt_soc_pcm_bt_dai";
		};

		MT_SOC_TDMRX_PCM@0x11220000 {
			compatible = "mediatek,mt_soc_tdm_capture";
		};

		MT_SOC_FM_MRGTX_PCM@0x11220000 {
			compatible = "mediatek,mt_soc_pcm_fmtx";
		};

		MT_SOC_UL2_PCM@0x11220000 {
			compatible = "mediatek,mt_soc_pcm_capture2";
		};

		MT_SOC_I2S0_AWB_PCM@0x11220000 {
			compatible = "mediatek,mt_soc_pcm_i2s0_awb";
		};

		MT_SOC_VOICE_MD2@0x11220000 {
			compatible = "mediatek,mt_soc_pcm_voice_md2";
		};

		MT_SOC_ROUTING_PCM@0x11220000 {
			compatible = "mediatek,mt_soc_pcm_routing";
		};

		MT_SOC_VOICE_MD2_BT@0x11220000 {
			compatible = "mediatek,mt_soc_pcm_voice_md2_bt";
		};

		MT_SOC_HP_IMPEDANCE_PCM@0x11220000 {
			compatible = "mediatek,Mt_soc_pcm_hp_impedance";
		};

		MT_SOC_CODEC_NAME@0x11220000 {
			compatible = "mediatek,mt_soc_codec_63xx";
		};

		MT_SOC_DUMMY_PCM@0x11220000 {
			compatible = "mediatek,mt_soc_pcm_dummy";
		};

		MT_SOC_CODEC_DUMMY_NAME@0x11220000 {
			compatible = "mediatek,mt_soc_codec_dummy";
		};

		MT_SOC_ROUTING_DAI_NAME@0x11220000 {
			compatible = "mediatek,mt_soc_dai_routing";
		};

		MT_SOC_DAI_NAME@0x11220000 {
			compatible = "mediatek,mt_soc_dai_stub";
		};

		MT_SOC_DL2_PCM@0x11220000 {
			compatible = "mediatek,mt_soc_pcm_dl2";
		};

		ICUSB@0x11270000 {
			compatible = "mediatek,ICUSB";
			reg = <0x11270000 0x10000 0x11210000 0x10000>;
			interrupts = <0x00 0x49 0x08>;
		};

		G3D_CONFIG@0x13000000 {
			compatible = "mediatek,G3D_CONFIG";
			reg = <0x13000000 0x1000>;
		};

		MALI@0x13040000 {
			compatible = "arm,malit760", "arm,mali-t76x", "arm,malit7xx", "arm,mali-midgard";
			reg = <0x13040000 0x4000>;
			interrupts = <0x00 0xe3 0x08>, <0x00 0xe2 0x08>, <0x00 0xe1 0x08>;
			interrupt-names = "JOB", "MMU", "GPU";
			clock-frequency = <0x29b92700>;
		};

		MMSYS_CONFIG@0x14000000 {
			compatible = "mediatek,MMSYS_CONFIG";
			reg = <0x14000000 0x1000>;
		};

		mdp_rdma@14001000 {
			compatible = "mediatek,mdp_rdma";
			reg = <0x14001000 0x1000>;
			interrupts = <0x00 0xb2 0x08>;
		};

		mdp_rsz0@14002000 {
			compatible = "mediatek,mdp_rsz0";
			reg = <0x14002000 0x1000>;
			interrupts = <0x00 0xb3 0x08>;
		};

		mdp_rsz1@14003000 {
			compatible = "mediatek,mdp_rsz1";
			reg = <0x14003000 0x1000>;
			interrupts = <0x00 0xb4 0x08>;
		};

		mdp_wdma@14004000 {
			compatible = "mediatek,mdp_wdma";
			reg = <0x14004000 0x1000>;
			interrupts = <0x00 0xb6 0x08>;
		};

		mdp_wrot@14005000 {
			compatible = "mediatek,mdp_wrot";
			reg = <0x14005000 0x1000>;
			interrupts = <0x00 0xb7 0x08>;
		};

		mdp_tdshp@14006000 {
			compatible = "mediatek,mdp_tdshp";
			reg = <0x14006000 0x1000>;
			interrupts = <0x00 0xb5 0x08>;
		};

		DISPSYS@0x10002000 {
			compatible = "mediatek,DISPSYS";
			reg = <0x14007000 0x1000 0x14008000 0x1000 0x14009000 0x1000 0x1400a000 0x1000 0x1400b000 0x1000 0x1400c000 0x1000 0x1400d000 0x1000 0x1400e000 0x1000 0x1400f000 0x1000 0x14010000 0x1000 0x14011000 0x1000 0x14014000 0x1000 0x14018000 0x1000 0x14015000 0x1000 0x14012000 0x1000 0x14013000 0x1000 0x14000000 0x1000 0x14016000 0x1000 0x14017000 0x1000 0x10215000 0x1000 0x10206000 0x1000 0x10000000 0x1000 0x100020f0 0x1000 0x100000a0 0x1000 0x1000c270 0x1000 0x1000c274 0x1000>;
			interrupts = <0x00 0xb8 0x08 0x00 0xb9 0x08 0x00 0xba 0x08 0x00 0xbb 0x08 0x00 0xbc 0x08 0x00 0xbd 0x08 0x00 0xbe 0x08 0x00 0xbf 0x08 0x00 0xc0 0x08 0x00 0xc1 0x08 0x00 0xc2 0x08 0x00 0x00 0x08 0x00 0xc6 0x08 0x00 0xb1 0x08 0x00 0xc3 0x08 0x00 0xc4 0x08 0x00 0x00 0x08 0x00 0x00 0x08 0x00 0x00 0x08>;
		};

		DISP_OVL0@0x14007000 {
			compatible = "mediatek,DISP_OVL0";
			reg = <0x14007000 0x1000>;
			interrupts = <0x00 0xb8 0x08>;
		};

		DISP_OVL1@0x14008000 {
			compatible = "mediatek,DISP_OVL1";
			reg = <0x14008000 0x1000>;
			interrupts = <0x00 0xb9 0x08>;
		};

		DISP_RDMA0@0x14009000 {
			compatible = "mediatek,DISP_RDMA0";
			reg = <0x14009000 0x1000>;
			interrupts = <0x00 0xc7 0x08>;
		};

		DISP_RDMA1@0x1400A000 {
			compatible = "mediatek,DISP_RDMA1";
			reg = <0x1400a000 0x1000>;
			interrupts = <0x00 0xc8 0x08>;
		};

		DISP_WDMA0@0x1400B000 {
			compatible = "mediatek,DISP_WDMA0";
			reg = <0x1400b000 0x1000>;
			interrupts = <0x00 0xc6 0x08>;
		};

		DISP_COLOR@0x1400C000 {
			compatible = "mediatek,DISP_COLOR";
			reg = <0x1400c000 0x1000>;
			interrupts = <0x00 0xbd 0x08>;
		};

		DISP_CCORR@0x1400D000 {
			compatible = "mediatek,DISP_CCORR";
			reg = <0x1400d000 0x1000>;
			interrupts = <0x00 0xbe 0x08>;
		};

		DISP_AAL@0x1400E000 {
			compatible = "mediatek,DISP_AAL";
			reg = <0x1400e000 0x1000>;
			interrupts = <0x00 0xbf 0x08>;
		};

		DISP_GAMMA@0x1400F000 {
			compatible = "mediatek,DISP_GAMMA";
			reg = <0x1400f000 0x1000>;
			interrupts = <0x00 0xc0 0x08>;
		};

		DISP_DITHER@0x14010000 {
			compatible = "mediatek,DISP_DITHER";
			reg = <0x14010000 0x1000>;
			interrupts = <0x00 0xc1 0x08>;
		};

		DSI_UFOE@0x14011000 {
			compatible = "mediatek,DSI_UFOE";
			reg = <0x14011000 0x1000>;
		};

		DSI0@0x14012000 {
			compatible = "mediatek,DSI0";
			reg = <0x14012000 0x1000>;
			interrupts = <0x00 0xc3 0x08>;
		};

		DPI0@0x14013000 {
			compatible = "mediatek,DPI0";
			reg = <0x14013000 0x1000>;
			interrupts = <0x00 0xc4 0x08>;
		};

		DISP_PWM0@0x14014000 {
			compatible = "mediatek,DISP_PWM0";
			reg = <0x14014000 0x1000>;
		};

		MM_MUTEX@0x14015000 {
			compatible = "mediatek,MM_MUTEX";
			reg = <0x14015000 0x1000>;
			interrupts = <0x00 0xb1 0x08>;
		};

		SMI_LARB0@0x14016000 {
			compatible = "mediatek,SMI_LARB0";
			reg = <0x14016000 0x1000>;
			interrupts = <0x00 0xcd 0x08>;
		};

		SMI_COMMON@0x14017000 {
			compatible = "mediatek,SMI_COMMON";
			reg = <0x14017000 0x1000 0x14016000 0x1000 0x16010000 0x1000 0x15001000 0x1000 0x17001000 0x1000 0x12002000 0x1000>;
		};

		DISP_WDMA1@0x14018000 {
			compatible = "mediatek,DISP_WDMA1";
			reg = <0x14018000 0x1000>;
		};

		UFOD_RDMA0@0x14019000 {
			compatible = "mediatek,UFOD_RDMA0";
			reg = <0x14019000 0x1000>;
		};

		UFOD_RDMA1@0x1401A000 {
			compatible = "mediatek,UFOD_RDMA1";
			reg = <0x1401a000 0x1000>;
		};

		IMGSYS_CONFIG@0x15000000 {
			compatible = "mediatek,IMGSYS_CONFIG";
			reg = <0x15000000 0x1000>;
		};

		SMI_LARB2@0x15001000 {
			compatible = "mediatek,SMI_LARB2";
			reg = <0x15001000 0x1000>;
			interrupts = <0x00 0xd9 0x08>;
		};

		ISPSYS@0x15000000 {
			compatible = "mediatek,ISPSYS";
			reg = <0x15004000 0x9000 0x1500d000 0x1000 0x15000000 0x10000 0x10217000 0x3000 0x10002000 0x1000>;
			interrupts = <0x00 0xdb 0x08 0x00 0xdc 0x08 0x00 0xdd 0x08 0x00 0xde 0x08 0x00 0xdf 0x08>;
		};

		KD_CAMERA_HW1@0x15008000 {
			compatible = "mediatek,CAMERA_HW";
			reg = <0x15008000 0x1000>;
		};

		KD_CAMERA_HW2@0x15008000 {
			compatible = "mediatek,CAMERA_HW2";
			reg = <0x15008000 0x1000>;
		};

		CAM0@0x15004000 {
			compatible = "mediatek,CAM0";
			reg = <0x15004000 0x2000>;
			interrupts = <0x00 0xdb 0x08>;
		};

		CAM1@0x15006000 {
			compatible = "mediatek,CAM1";
			reg = <0x15006000 0x1000>;
			interrupts = <0x00 0xdc 0x08>;
		};

		CAM2@0x15007000 {
			compatible = "mediatek,CAM2";
			reg = <0x15007000 0x1000>;
			interrupts = <0x00 0xdd 0x08>;
		};

		SENINF@0x15008000 {
			compatible = "mediatek,SENINF";
			reg = <0x15008000 0x1000>;
		};

		CAMSV0@0x15009000 {
			compatible = "mediatek,CAMSV0";
			reg = <0x15009000 0x800>;
			interrupts = <0x00 0xde 0x08>;
		};

		CAMSV1@0x15009800 {
			compatible = "mediatek,CAMSV1";
			reg = <0x15009800 0x800>;
			interrupts = <0x00 0xdf 0x08>;
		};

		FD@0x1500B000 {
			compatible = "mediatek,FD";
			reg = <0x1500b000 0x1000>;
			interrupts = <0x00 0xe0 0x08>;
		};

		MIPI_RX@0x1500C000 {
			compatible = "mediatek,MIPI_RX";
			reg = <0x1500c000 0x1000>;
		};

		CAM0_INNER@0x1500D000 {
			compatible = "mediatek,CAM0_INNER";
			reg = <0x1500d000 0x1000>;
		};

		CAM2_INNER@0x1500E000 {
			compatible = "mediatek,CAM2_INNER";
			reg = <0x1500e000 0x1000>;
		};

		CAM3_INNER@0x1500F000 {
			compatible = "mediatek,CAM3_INNER";
			reg = <0x1500f000 0x1000>;
		};

		VDEC_GCON@16000000 {
			compatible = "mediatek,VDEC_GCON";
			reg = <0x16000000 0x10000>;
		};

		SMI_LARB1@16010000 {
			compatible = "mediatek,SMI_LARB1";
			reg = <0x16010000 0x10000>;
			interrupts = <0x00 0xd5 0x08>;
		};

		VDEC@16020000 {
			compatible = "mediatek,VDEC";
			reg = <0x16020000 0x10000>;
			interrupts = <0x00 0xd4 0x08>;
		};

		MJC_CONFIG@0x12000000 {
			compatible = "mediatek,MJC_CONFIG";
			reg = <0x12000000 0x1000>;
		};

		MJC_TOP@0x12001000 {
			compatible = "mediatek,MJC_TOP";
			reg = <0x12001000 0x1000>;
			interrupts = <0x00 0xd7 0x08>;
		};

		SMI_LARB5@0x12002000 {
			compatible = "mediatek,SMI_LARB5";
			reg = <0x12002000 0x1000>;
		};

		VENC_GCON@17000000 {
			compatible = "mediatek,VENC_GCON";
			reg = <0x17000000 0x1000>;
		};

		SMI_LARB3@17001000 {
			compatible = "mediatek,SMI_LARB3";
			reg = <0x17001000 0x1000>;
			interrupts = <0x00 0xcf 0x08>;
		};

		VENC@17002000 {
			compatible = "mediatek,VENC";
			reg = <0x17002000 0x1000>;
			interrupts = <0x00 0xce 0x08>;
		};

		JPGENC@17003000 {
			compatible = "mediatek,JPGENC";
			reg = <0x17003000 0x1000>;
			interrupts = <0x00 0xd0 0x08>;
		};

		JPGDEC@17004000 {
			compatible = "mediatek,JPGDEC";
			reg = <0x17004000 0x1000>;
			interrupts = <0x00 0xd3 0x08>;
		};

		gpio@0x10001e00 {
			compatible = "mediatek,fpga_gpio";
			reg = <0x10001e00 0x100>;
		};

		MDCLDMA@0x200F0000 {
			compatible = "mediatek,MDCLDMA";
			reg = <0x200f0000 0x3000 0x200e0000 0x3000 0x10209000 0x1000>;
			cell-index = <0x00>;
			interrupts = <0x00 0xe9 0x04 0x00 0x8b 0x08 0x00 0xe8 0x02>;
			cldma,major = <0xb8>;
			cldma,minor_base = <0x00>;
			cldma,capability = <0x02>;
			md_smem_size = <0x200000>;
		};

		HDMI@0 {
			compatible = "mediatek,HDMI";
		};

		hwmsensor@0 {
			compatible = "mediatek,hwmsensor";
		};

		gsensor@0 {
			compatible = "mediatek,gsensor";
		};

		als_ps@0 {
			compatible = "mediatek,als_ps";
		};

		m_acc_pl@0 {
			compatible = "mediatek,m_acc_pl";
		};

		m_alsps_pl@0 {
			compatible = "mediatek,m_alsps_pl";
		};

		sensorHub@0 {
			compatible = "mediatek,sensorHub";
		};

		shf@0 {
			compatible = "mediatek,shf";
		};

		m_batch_pl@0 {
			compatible = "mediatek,m_batch_pl";
		};

		gyroscope@0 {
			compatible = "mediatek,gyroscope";
		};

		m_gyro_pl@0 {
			compatible = "mediatek,m_gyro_pl";
		};

		barometer@0 {
			compatible = "mediatek,barometer";
		};

		m_baro_pl@0 {
			compatible = "mediatek,m_baro_pl";
		};

		msensor@0 {
			compatible = "mediatek,msensor";
		};

		m_mag_pl@0 {
			compatible = "mediatek,m_mag_pl";
		};

		orientation@0 {
			compatible = "mediatek,orientation";
		};

		pedometer@0 {
			compatible = "mediatek,pedometer";
		};

		m_pdr_pl@0 {
			compatible = "mediatek,m_pdr_pl";
		};

		step_counter@0 {
			compatible = "mediatek,step_counter";
		};

		m_step_c_pl@0 {
			compatible = "mediatek,m_step_c_pl";
		};

		in_pocket@0 {
			compatible = "mediatek,in_pocket";
		};

		m_inpk_pl@0 {
			compatible = "mediatek,m_inpk_pl";
		};

		shake@0 {
			compatible = "mediatek,shake";
		};

		m_shk_pl@0 {
			compatible = "mediatek,m_shk_pl";
		};

		face_down@0 {
			compatible = "mediatek,face_down";
		};

		m_fdn_pl@0 {
			compatible = "mediatek,m_fdn_pl";
		};

		activity@0 {
			compatible = "mediatek,activity";
		};

		m_act_pl@0 {
			compatible = "mediatek,m_act_pl";
		};

		heart_rate@0 {
			compatible = "mediatek,heart_rate";
		};

		m_hrm_pl@0 {
			compatible = "mediatek,m_hrm_pl";
		};

		tilt_detector@0 {
			compatible = "mediatek,tilt_detector";
		};

		m_tilt_pl@0 {
			compatible = "mediatek,m_tilt_pl";
		};

		wake_gesture@0 {
			compatible = "mediatek,wake_gesture";
		};

		m_wag_pl@0 {
			compatible = "mediatek,m_wag_pl";
		};

		glance_gesture@0 {
			compatible = "mediatek,glance_gesture";
		};

		m_glg_pl@0 {
			compatible = "mediatek,m_glg_pl";
		};

		pick_up@0 {
			compatible = "mediatek,pick_up";
		};

		m_pkup_pl@0 {
			compatible = "mediatek,m_pkup_pl";
		};

		MTKFB@0 {
			compatible = "mediatek,MTKFB";
		};

		CHIPID@08000000 {
			compatible = "mediatek,CHIPID";
			reg = <0x8000000 0x04 0x8000004 0x04 0x8000008 0x04 0x800000c 0x04>;
		};

		CQDMA@0x10212c00 {
			compatible = "mediatek,CQDMA";
			reg = <0x10212c00 0x1000>;
			interrupts = <0x00 0x8f 0x08>;
			nr_channel = <0x01>;
		};

		l2c_share@0x10200000 {
			compatible = "mediatek,l2c_share";
			reg = <0x10200000 0x04 0x10200200 0x04>;
			mediatek,l2c-share-cluster-num = <0x02>;
			mediatek,l2c-cluster-borrow = <0x01>;
			mediatek,l2c-cluster-return = <0x03>;
		};
	};

	psci {
		compatible = "arm,psci";
		method = "smc";
		cpu_suspend = <0x84000001>;
		cpu_off = <0x84000002>;
		cpu_on = <0x84000003>;
		affinity_info = <0x84000004>;
	};

	MOBICORE {
		compatible = "trustonic,mobicore";
		interrupts = <0x00 0xf8 0x01>;
	};

	trusty {
		compatible = "android,trusty-smc-v1";
		ranges;
		#address-cells = <0x02>;
		#size-cells = <0x02>;

		irq {
			compatible = "android,trusty-irq-v1";
		};

		log {
			compatible = "android,trusty-log-v1";
		};

		virtio {
			compatible = "android,trusty-virtio-v1";
		};
	};

        TOUCH@0 {
            compatible = "mediatek, TPD";
            tpd-resolution = <1200 1920>;
            eint-gpio = <139 0>;
            rst-gpio = <144 0>;
        };
};
